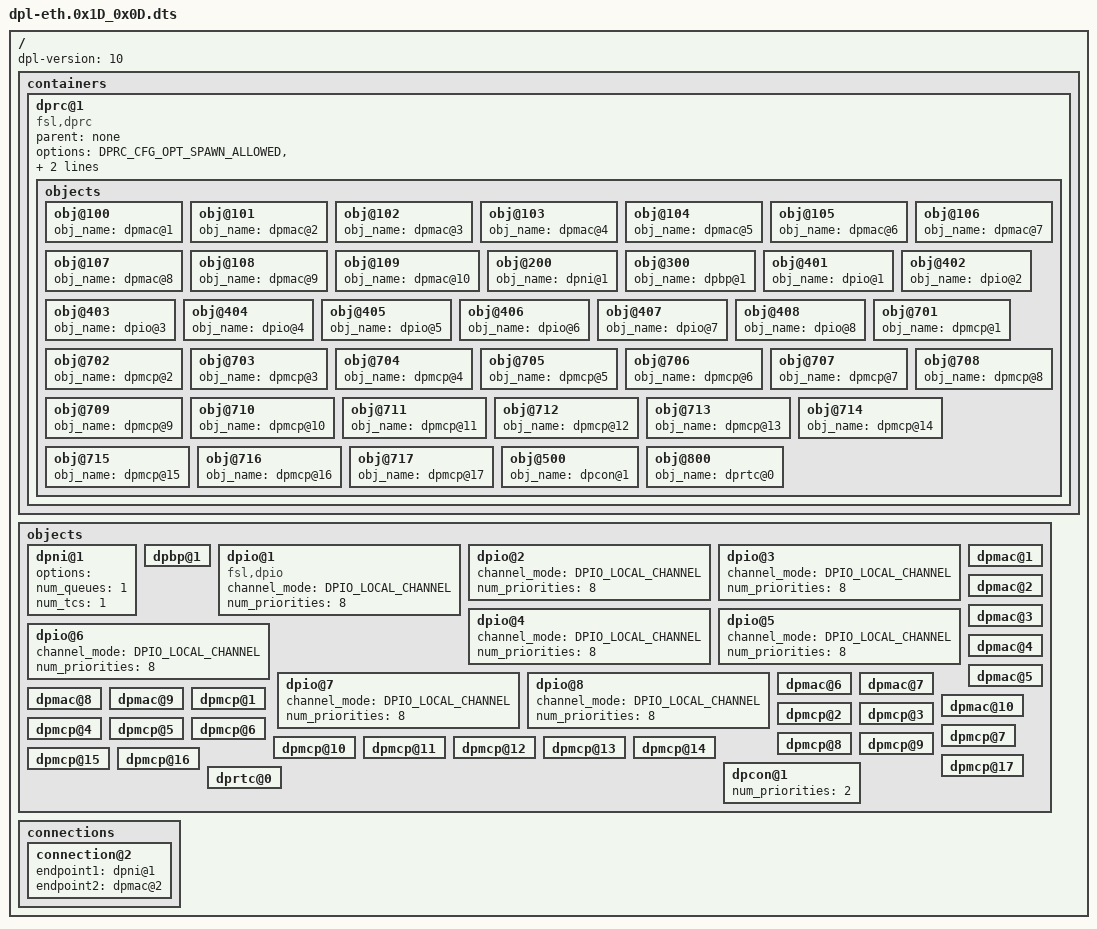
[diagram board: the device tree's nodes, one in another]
/*
 * Copyright 2015 Freescale Semiconductor, Inc.
 * "Bootstrap DPL" for ls1088a featuring SerDes 0x1D_0x0D.
 * This together with the available DPMCP objects should be enough to boot Linux
 * and to allow the dynamic addition of other objects to the Linux container,
 * using the 'restool' utility.
 */

/dts-v1/;
/ {
	dpl-version = <10>;
	/*****************************************************************
	 * Containers
	 *****************************************************************/
	containers {
		dprc@1 {
			compatible = "fsl,dprc";
			parent = "none";
			options = "DPRC_CFG_OPT_SPAWN_ALLOWED" , "DPRC_CFG_OPT_ALLOC_ALLOWED", "DPRC_CFG_OPT_IRQ_CFG_ALLOWED";
			objects {
				/* ------------- MACs --------------*/
				obj@100 {
					obj_name = "dpmac@1";
				};
				obj@101 {
					obj_name = "dpmac@2";
				};
				obj@102 {
					obj_name = "dpmac@3";
				};
				obj@103 {
					obj_name = "dpmac@4";
				};
				obj@104 {
					obj_name = "dpmac@5";
				};
				obj@105 {
					obj_name = "dpmac@6";
				};
				obj@106 {
					obj_name = "dpmac@7";
				};
				obj@107 {
					obj_name = "dpmac@8";
				};
				obj@108 {
					obj_name = "dpmac@9";
				};
				obj@109 {
					obj_name = "dpmac@10";
				};

				/* ------------ DPNIs --------------*/
				obj@200 {
					obj_name = "dpni@1";
				};

				/* ------------ DPBPs --------------*/
				obj@300 {
					obj_name="dpbp@1";
				};

				/* ------------ DPIOs --------------*/
				obj@401 {
					obj_name = "dpio@1";
				};
				obj@402 {
					obj_name = "dpio@2";
				};
				obj@403 {
					obj_name = "dpio@3";
				};
				obj@404 {
					obj_name = "dpio@4";
				};
				obj@405 {
					obj_name = "dpio@5";
				};
				obj@406 {
					obj_name = "dpio@6";
				};
				obj@407 {
					obj_name = "dpio@7";
				};
				obj@408 {
					obj_name = "dpio@8";
				};

				/* ------------ DPMCPs --------------*/
				obj@701 {
					obj_name="dpmcp@1";
				};
				obj@702 {
					obj_name="dpmcp@2";
				};
				obj@703 {
					obj_name="dpmcp@3";
				};
				obj@704 {
					obj_name="dpmcp@4";
				};
				obj@705 {
					obj_name="dpmcp@5";
				};
				obj@706 {
					obj_name="dpmcp@6";
				};
				obj@707 {
					obj_name="dpmcp@7";
				};
				obj@708 {
					obj_name="dpmcp@8";
				};
				obj@709 {
					obj_name="dpmcp@9";
				};
				obj@710 {
					obj_name="dpmcp@10";
				};
				obj@711 {
					obj_name="dpmcp@11";
				};
				obj@712 {
					obj_name="dpmcp@12";
				};
				obj@713 {
					obj_name="dpmcp@13";
				};
				obj@714 {
					obj_name="dpmcp@14";
				};
				obj@715 {
					obj_name="dpmcp@15";
				};
				obj@716 {
					obj_name="dpmcp@16";
				};
				obj@717 {
					obj_name="dpmcp@17";
				};

				/* ------------ DPCON --------------*/
				obj@500 {
					obj_name="dpcon@1";
				};

				/* ------------ DPRTC --------------*/
				obj@800 {
					obj_name="dprtc@0";
				};
			};
		};
	};

	/*****************************************************************
	 * Objects
	 *****************************************************************/
	objects {

		/* ------------ DPNI --------------*/
		dpni@1 {
			options = "";
			num_queues = <1>;
			num_tcs = <1>;
		};

		/* ------------ DPBP --------------*/
		dpbp@1 {
		};

		/* ------------ DPIO --------------*/
		dpio@1 {
			compatible = "fsl,dpio";
			channel_mode = "DPIO_LOCAL_CHANNEL";
			num_priorities = <8>;
		};
		dpio@2 {
			channel_mode = "DPIO_LOCAL_CHANNEL";
			num_priorities = <8>;
		};
		dpio@3 {
			channel_mode = "DPIO_LOCAL_CHANNEL";
			num_priorities = <8>;
		};
		dpio@4 {
			channel_mode = "DPIO_LOCAL_CHANNEL";
			num_priorities = <8>;
		};
		dpio@5 {
			channel_mode = "DPIO_LOCAL_CHANNEL";
			num_priorities = <8>;
		};
		dpio@6 {
			channel_mode = "DPIO_LOCAL_CHANNEL";
			num_priorities = <8>;
		};
		dpio@7 {
			channel_mode = "DPIO_LOCAL_CHANNEL";
			num_priorities = <8>;
		};
		dpio@8 {
			channel_mode = "DPIO_LOCAL_CHANNEL";
			num_priorities = <8>;
		};

		/* ------------ DPMAC --------------*/
		dpmac@1 {
		};
		dpmac@2 {
		};
		dpmac@3 {
		};
		dpmac@4 {
		};
		dpmac@5 {
		};
		dpmac@6 {
		};
		dpmac@7 {
		};
		dpmac@8 {
		};
		dpmac@9 {
		};
		dpmac@10 {
		};

		/* ------------ DPMCP --------------*/
		dpmcp@1 {
		};
		dpmcp@2 {
		};
		dpmcp@3 {
		};
		dpmcp@4 {
		};
		dpmcp@5 {
		};
		dpmcp@6 {
		};
		dpmcp@7 {
		};
		dpmcp@8 {
		};
		dpmcp@9 {
		};
		dpmcp@10 {
		};
		dpmcp@11 {
		};
		dpmcp@12 {
		};
		dpmcp@13 {
		};
		dpmcp@14 {
		};
		dpmcp@15 {
		};
		dpmcp@16 {
		};
		dpmcp@17 {
		};

		/* ------------ DPCON --------------*/
		dpcon@1 {
			num_priorities=<2>;
		};

		/* ------------ DPRTC --------------*/
		dprtc@0 {
		};
	};

	/*****************************************************************
	 * Connections
	 *****************************************************************/
	connections {
		connection@2{
			endpoint1 = "dpni@1";
			endpoint2 = "dpmac@2";
		};
	};
};
